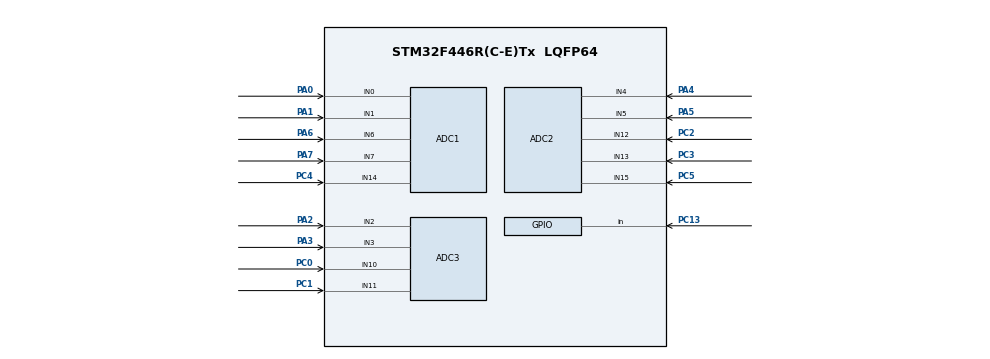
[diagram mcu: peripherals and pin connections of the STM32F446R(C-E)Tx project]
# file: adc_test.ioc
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ADC1.Channel-3\#ChannelRegularConversion=ADC_CHANNEL_1
ADC1.NbrOfConversionFlag=1
ADC1.Rank-3\#ChannelRegularConversion=1
ADC1.SamplingTime-3\#ChannelRegularConversion=ADC_SAMPLETIME_3CYCLES
ADC1.master=1
ADC2.Channel-0\#ChannelRegularConversion=ADC_CHANNEL_12
ADC2.NbrOfConversionFlag=1
ADC2.Rank-0\#ChannelRegularConversion=1
ADC2.SamplingTime-0\#ChannelRegularConversion=ADC_SAMPLETIME_3CYCLES
ADC3.Channel-0\#ChannelRegularConversion=ADC_CHANNEL_10
ADC3.NbrOfConversionFlag=1
ADC3.Rank-0\#ChannelRegularConversion=1
ADC3.SamplingTime-0\#ChannelRegularConversion=ADC_SAMPLETIME_3CYCLES
Dma.ADC1.0.Direction=DMA_PERIPH_TO_MEMORY
Dma.ADC1.0.FIFOMode=DMA_FIFOMODE_DISABLE
Dma.ADC1.0.Instance=DMA2_Stream0
Dma.ADC1.0.MemDataAlignment=DMA_MDATAALIGN_HALFWORD
Dma.ADC1.0.MemInc=DMA_MINC_ENABLE
Dma.ADC1.0.Mode=DMA_CIRCULAR
Dma.ADC1.0.PeriphDataAlignment=DMA_PDATAALIGN_HALFWORD
Dma.ADC1.0.PeriphInc=DMA_PINC_DISABLE
Dma.ADC1.0.Priority=DMA_PRIORITY_LOW
Dma.Request0=ADC1
Mcu.Family=STM32F4
Mcu.Name=STM32F446R(C-E)Tx
Mcu.Package=LQFP64
NVIC.DMA2_Stream0_IRQn=true\:0\:0\:false\:false\:true\:false\:true\:true
NVIC.PriorityGroup=NVIC_PRIORITYGROUP_4
PA0-WKUP.Signal=ADCx_IN0
PA1.Signal=ADCx_IN1
PA2.Signal=ADCx_IN2
PA3.Signal=ADCx_IN3
PA4.Signal=ADCx_IN4
PA5.Signal=ADCx_IN5
PA6.Signal=ADCx_IN6
PA7.Signal=ADCx_IN7
PC0.Signal=ADCx_IN10
PC1.Signal=ADCx_IN11
PC13.Signal=GPIO_Input
PC2.Signal=ADCx_IN12
PC3.Signal=ADCx_IN13
PC4.Signal=ADCx_IN14
PC5.Signal=ADCx_IN15
ProjectManager.HeapSize=0x200
ProjectManager.StackSize=0x400
ProjectManager.TargetToolchain=STM32CubeIDE
RCC.CortexFreq_Value=16000000
RCC.USBFreq_Value=96000000
RCC.VCOOutputFreq_Value=192000000
SH.ADCx_IN0.0=ADC1_IN0,IN0
SH.ADCx_IN1.0=ADC1_IN1,IN1
SH.ADCx_IN10.0=ADC3_IN10,IN10
SH.ADCx_IN11.0=ADC3_IN11,IN11
SH.ADCx_IN12.0=ADC2_IN12,IN12
SH.ADCx_IN13.0=ADC2_IN13,IN13
SH.ADCx_IN14.0=ADC1_IN14,IN14
SH.ADCx_IN15.0=ADC2_IN15,IN15
SH.ADCx_IN2.0=ADC3_IN2,IN2
SH.ADCx_IN3.0=ADC3_IN3,IN3
SH.ADCx_IN4.0=ADC2_IN4,IN4
SH.ADCx_IN5.0=ADC2_IN5,IN5
SH.ADCx_IN6.0=ADC1_IN6,IN6
SH.ADCx_IN7.0=ADC1_IN7,IN7
board=NUCLEO-F446RE

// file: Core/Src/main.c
/* USER CODE BEGIN Header */
/**
  ******************************************************************************
  * @file           : main.c
  * @brief          : Main program body
  ******************************************************************************
  * @attention
  *
  * Copyright (c) 2026 STMicroelectronics.
  * All rights reserved.
  *
  * This software is licensed under terms that can be found in the LICENSE file
  * in the root directory of this software component.
  * If no LICENSE file comes with this software, it is provided AS-IS.
  *
  ******************************************************************************
  */
/* USER CODE END Header */
#include "main.h"

ADC_HandleTypeDef hadc1;
ADC_HandleTypeDef hadc2;
ADC_HandleTypeDef hadc3;
DMA_HandleTypeDef hdma_adc1;

/* USER CODE BEGIN PV */
uint32_t adc_val;
/* USER CODE END PV */

void SystemClock_Config(void);
static void MX_GPIO_Init(void);
static void MX_DMA_Init(void);
static void MX_ADC1_Init(void);
static void MX_ADC2_Init(void);
static void MX_ADC3_Init(void);

int main(void)
{

  /* MCU Configuration--------------------------------------------------------*/

  /* Reset of all peripherals, Initializes the Flash interface and the Systick. */
  HAL_Init();

  /* Configure the system clock */
  SystemClock_Config();

  /* Initialize all configured peripherals */
  MX_GPIO_Init();
  MX_DMA_Init();
  MX_ADC1_Init();
  MX_ADC2_Init();
  MX_ADC3_Init();
  /* USER CODE BEGIN 2 */
//  HAL_ADC_MspInit(&hadc1);
  HAL_ADC_Start_DMA(&hadc1,(uint32_t*)&adc_val,1);
  /* USER CODE END 2 */

  /* Infinite loop */
  while (1)
  {

  }
}

void SystemClock_Config(void)
{
  RCC_OscInitTypeDef RCC_OscInitStruct = {0};
  RCC_ClkInitTypeDef RCC_ClkInitStruct = {0};

  /** Configure the main internal regulator output voltage
  */
  __HAL_RCC_PWR_CLK_ENABLE();
  __HAL_PWR_VOLTAGESCALING_CONFIG(PWR_REGULATOR_VOLTAGE_SCALE3);

  /** Initializes the RCC Oscillators according to the specified parameters
  * in the RCC_OscInitTypeDef structure.
  */
  RCC_OscInitStruct.OscillatorType = RCC_OSCILLATORTYPE_HSI;
  RCC_OscInitStruct.HSIState = RCC_HSI_ON;
  RCC_OscInitStruct.HSICalibrationValue = RCC_HSICALIBRATION_DEFAULT;
  RCC_OscInitStruct.PLL.PLLState = RCC_PLL_NONE;
  if (HAL_RCC_OscConfig(&RCC_OscInitStruct) != HAL_OK)
  {
    Error_Handler();
  }

  /** Initializes the CPU, AHB and APB buses clocks
  */
  RCC_ClkInitStruct.ClockType = RCC_CLOCKTYPE_HCLK|RCC_CLOCKTYPE_SYSCLK
                              |RCC_CLOCKTYPE_PCLK1|RCC_CLOCKTYPE_PCLK2;
  RCC_ClkInitStruct.SYSCLKSource = RCC_SYSCLKSOURCE_HSI;
  RCC_ClkInitStruct.AHBCLKDivider = RCC_SYSCLK_DIV1;
  RCC_ClkInitStruct.APB1CLKDivider = RCC_HCLK_DIV1;
  RCC_ClkInitStruct.APB2CLKDivider = RCC_HCLK_DIV1;

  if (HAL_RCC_ClockConfig(&RCC_ClkInitStruct, FLASH_LATENCY_0) != HAL_OK)
  {
    Error_Handler();
  }
}

static void MX_ADC1_Init(void)
{

  ADC_ChannelConfTypeDef sConfig = {0};

  /** Configure the global features of the ADC (Clock, Resolution, Data Alignment and number of conversion)
  */
  hadc1.Instance = ADC1;
  hadc1.Init.ClockPrescaler = ADC_CLOCK_SYNC_PCLK_DIV2;
  hadc1.Init.Resolution = ADC_RESOLUTION_12B;
  hadc1.Init.ScanConvMode = DISABLE;
  hadc1.Init.ContinuousConvMode = DISABLE;
  hadc1.Init.DiscontinuousConvMode = DISABLE;
  hadc1.Init.ExternalTrigConvEdge = ADC_EXTERNALTRIGCONVEDGE_NONE;
  hadc1.Init.ExternalTrigConv = ADC_SOFTWARE_START;
  hadc1.Init.DataAlign = ADC_DATAALIGN_RIGHT;
  hadc1.Init.NbrOfConversion = 1;
  hadc1.Init.DMAContinuousRequests = DISABLE;
  hadc1.Init.EOCSelection = ADC_EOC_SINGLE_CONV;
  if (HAL_ADC_Init(&hadc1) != HAL_OK)
  {
    Error_Handler();
  }

  /** Configure for the selected ADC regular channel its corresponding rank in the sequencer and its sample time.
  */
  sConfig.Channel = ADC_CHANNEL_1;
  sConfig.Rank = 1;
  sConfig.SamplingTime = ADC_SAMPLETIME_3CYCLES;
  if (HAL_ADC_ConfigChannel(&hadc1, &sConfig) != HAL_OK)
  {
    Error_Handler();
  }

}

static void MX_ADC2_Init(void)
{

  ADC_ChannelConfTypeDef sConfig = {0};

  /** Configure the global features of the ADC (Clock, Resolution, Data Alignment and number of conversion)
  */
  hadc2.Instance = ADC2;
  hadc2.Init.ClockPrescaler = ADC_CLOCK_SYNC_PCLK_DIV2;
  hadc2.Init.Resolution = ADC_RESOLUTION_12B;
  hadc2.Init.ScanConvMode = DISABLE;
  hadc2.Init.ContinuousConvMode = DISABLE;
  hadc2.Init.DiscontinuousConvMode = DISABLE;
  hadc2.Init.ExternalTrigConvEdge = ADC_EXTERNALTRIGCONVEDGE_NONE;
  hadc2.Init.ExternalTrigConv = ADC_SOFTWARE_START;
  hadc2.Init.DataAlign = ADC_DATAALIGN_RIGHT;
  hadc2.Init.NbrOfConversion = 1;
  hadc2.Init.DMAContinuousRequests = DISABLE;
  hadc2.Init.EOCSelection = ADC_EOC_SINGLE_CONV;
  if (HAL_ADC_Init(&hadc2) != HAL_OK)
  {
    Error_Handler();
  }

  /** Configure for the selected ADC regular channel its corresponding rank in the sequencer and its sample time.
  */
  sConfig.Channel = ADC_CHANNEL_12;
  sConfig.Rank = 1;
  sConfig.SamplingTime = ADC_SAMPLETIME_3CYCLES;
  if (HAL_ADC_ConfigChannel(&hadc2, &sConfig) != HAL_OK)
  {
    Error_Handler();
  }

}

static void MX_ADC3_Init(void)
{

  ADC_ChannelConfTypeDef sConfig = {0};

  /** Configure the global features of the ADC (Clock, Resolution, Data Alignment and number of conversion)
  */
  hadc3.Instance = ADC3;
  hadc3.Init.ClockPrescaler = ADC_CLOCK_SYNC_PCLK_DIV2;
  hadc3.Init.Resolution = ADC_RESOLUTION_12B;
  hadc3.Init.ScanConvMode = DISABLE;
  hadc3.Init.ContinuousConvMode = DISABLE;
  hadc3.Init.DiscontinuousConvMode = DISABLE;
  hadc3.Init.ExternalTrigConvEdge = ADC_EXTERNALTRIGCONVEDGE_NONE;
  hadc3.Init.ExternalTrigConv = ADC_SOFTWARE_START;
  hadc3.Init.DataAlign = ADC_DATAALIGN_RIGHT;
  hadc3.Init.NbrOfConversion = 1;
  hadc3.Init.DMAContinuousRequests = DISABLE;
  hadc3.Init.EOCSelection = ADC_EOC_SINGLE_CONV;
  if (HAL_ADC_Init(&hadc3) != HAL_OK)
  {
    Error_Handler();
  }

  /** Configure for the selected ADC regular channel its corresponding rank in the sequencer and its sample time.
  */
  sConfig.Channel = ADC_CHANNEL_10;
  sConfig.Rank = 1;
  sConfig.SamplingTime = ADC_SAMPLETIME_3CYCLES;
  if (HAL_ADC_ConfigChannel(&hadc3, &sConfig) != HAL_OK)
  {
    Error_Handler();
  }

}

static void MX_DMA_Init(void)
{

  /* DMA controller clock enable */
  __HAL_RCC_DMA2_CLK_ENABLE();

  /* DMA interrupt init */
  /* DMA2_Stream0_IRQn interrupt configuration */
  HAL_NVIC_SetPriority(DMA2_Stream0_IRQn, 0, 0);
  HAL_NVIC_EnableIRQ(DMA2_Stream0_IRQn);

}

static void MX_GPIO_Init(void)
{
  GPIO_InitTypeDef GPIO_InitStruct = {0};

  /* GPIO Ports Clock Enable */
  __HAL_RCC_GPIOC_CLK_ENABLE();
  __HAL_RCC_GPIOA_CLK_ENABLE();

  /*Configure GPIO pin : PC13 */
  GPIO_InitStruct.Pin = GPIO_PIN_13;
  GPIO_InitStruct.Mode = GPIO_MODE_INPUT;
  GPIO_InitStruct.Pull = GPIO_NOPULL;
  HAL_GPIO_Init(GPIOC, &GPIO_InitStruct);

}

void Error_Handler(void)
{
  __disable_irq();
  while (1)
  {
  }
}
